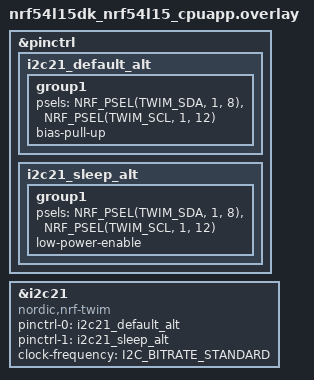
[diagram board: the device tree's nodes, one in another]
&pinctrl {
        i2c21_default_alt: i2c21_default_alt {
                group1 {
                        psels = <NRF_PSEL(TWIM_SDA, 1, 8)>,
                                <NRF_PSEL(TWIM_SCL, 1, 12)>;
                        bias-pull-up;
                };
        };

        i2c21_sleep_alt: i2c21_sleep_alt {
                group1 {
                        psels = <NRF_PSEL(TWIM_SDA, 1, 8)>,
                                <NRF_PSEL(TWIM_SCL, 1, 12)>;
                        low-power-enable;
                };
        };
};

&i2c21 {
        compatible = "nordic,nrf-twim";
        status = "okay";
        pinctrl-0 = <&i2c21_default_alt>;
        pinctrl-1 = <&i2c21_sleep_alt>;
        pinctrl-names = "default", "sleep";
        clock-frequency = <I2C_BITRATE_STANDARD>;
};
